# APM32F425 register map
File version: 1.0
CPU: CM4 r1p0, little endian, no MPU, no FPU, 4 interrupt priority bits
Registers are 32-bit, read-write, reset 0x0 unless marked. A register's access mark holds for its fields unless they carry their own. Offsets are from the block's base; [hi:lo] are bit positions.

## Ethernet_DMA — Ethernet: DMA controller operation
Base 0x40029000
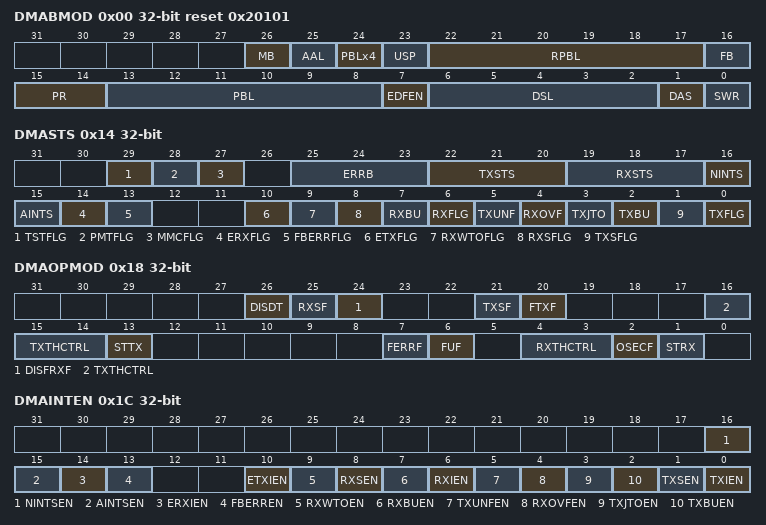
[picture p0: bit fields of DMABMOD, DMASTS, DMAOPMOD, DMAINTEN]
0x00 DMABMOD reset 0x20101 — Ethernet DMA bus mode register
  [26] MB — Mixed Burst
  [25] AAL — Address-Aligned Beats
  [24] PBLx4 — PBLx4 Mode
  [23] USP — Use Separate PBL
  [22:17] RPBL — Rx DMA PBL
  [16] FB — Fixed Burst
  [15:14] PR — Priority Ratio
  [13:8] PBL — Programmable Burst Length
  [7] EDFEN — Enhanced Descriptor Format Enable
  [6:2] DSL — Descriptor Skip Length
  [1] DAS — DMA Arbitration Scheme
  [0] SWR — Software Reset
0x04 DMATXPD — Ethernet DMA transmit poll demand register
  [31:0] TXPD — Transmit Poll Demand
0x08 DMARXPD — EHERNET DMA receive poll demand register
  [31:0] RXPD — Receive Poll Demand
0x0C DMARXDLADDR — Ethernet DMA receive descriptor list address register
  [31:0] RXSTA — Start of Receive List
0x10 DMATXDLADDR — Ethernet DMA transmit descriptor list address register
  [31:0] TXSTA — Start of Transmit List
0x14 DMASTS access per field — Ethernet DMA status register
  [29] TSTFLG ro — Timestamp Trigger Flag
  [28] PMTFLG ro — PMT Flag
  [27] MMCFLG ro — MMC Flag
  [25:23] ERRB ro — Error Bits
  [22:20] TXSTS ro — Transmit Process State
  [19:17] RXSTS ro — Receive Process State
  [16] NINTS rw — Normal Interrupt Summary
  [15] AINTS rw — Abnormal Interrupt Summary
  [14] ERXFLG rw — Early Receive Flag
  [13] FBERRFLG rw — Fatal Bus Error Flag
  [10] ETXFLG rw — Early Transmit Flag
  [9] RXWTOFLG rw — Receive Watchdog Timeout Flag
  [8] RXSFLG rw — Receive Stopped Flag
  [7] RXBU rw — Receive Buffer Unavailable
  [6] RXFLG rw — Receive Flag
  [5] TXUNF rw — Transmit Underflow
  [4] RXOVF rw — Receive Overflow
  [3] TXJTO rw — Transmit Jabber Timeout
  [2] TXBU rw — Transmit Buffer Unavailable
  [1] TXSFLG rw — Transmit Stopped Flag
  [0] TXFLG rw — Transmit Flag
0x18 DMAOPMOD — Ethernet DMA operation mode register
  [26] DISDT — Disable Dropping of TCP/IP Checksum Error Frames
  [25] RXSF — Receive Store and Forward
  [24] DISFRXF — Disable Flushing of Received Frames
  [21] TXSF — Transmit Store and Forward
  [20] FTXF — Flush Transmit FIFO
  [16:14] TXTHCTRL — Transmit Threshold Control
  [13] STTX — Start or Stop Transmission Command
  [7] FERRF — Forward Error Frames
  [6] FUF — Forward Undersized Good Frames
  [4:3] RXTHCTRL — Receive Threshold Control
  [2] OSECF — Operate on Second Frame
  [1] STRX — Start or Stop Receive
0x1C DMAINTEN — Ethernet DMA interrupt enable register
  [16] NINTSEN — Normal Interrupt Summary Enable
  [15] AINTSEN — Abnormal Interrupt Summary Enable
  [14] ERXIEN — Early Receive Interrupt Enable
  [13] FBERREN — Fatal Bus Error Enable
  [10] ETXIEN — Early Transmit Interrupt Enable
  [9] RXWTOEN — Receive Watchdog Timeout Enable
  [8] RXSEN — Receive Stopped Enable
  [7] RXBUEN — Receive Buffer Unavailable Enable
  [6] RXIEN — Receive Interrupt Enable
  [5] TXUNFEN — Transmit Underflow Interrupt Enable
  [4] RXOVFEN — Receive Overflow Interrupt Enable
  [3] TXJTOEN — Transmit Jabber Timeout Enable
  [2] TXBUEN — Transmit Buffer Unavailable Enable
  [1] TXSEN — Transmit Stopped Enable
  [0] TXIEN — Transmit Interrupt Enable
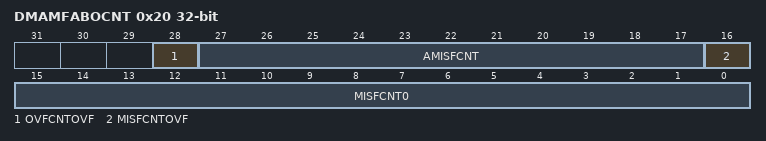
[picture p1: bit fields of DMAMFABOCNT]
0x20 DMAMFABOCNT — Ethernet DMA missed frame and buffer overflow counter register
  [28] OVFCNTOVF — Overflow Bit for FIFO Overflow Counter
  [27:17] AMISFCNT — Application Missed Frame Counter
  [16] MISFCNTOVF — Overflow Bit for Missed Frame Counter
  [15:0] MISFCNT0 — Missed Frame Counter
0x24 DMARXFLGWDT — Ethernet DMA receive status watchdog timer register
  [7:0] RXWDTCNT — RXFLG Watchdog Timer Count
0x48 DMAHTXD ro — Ethernet DMA current host transmit descriptor register
  [31:0] HTXDADDRP — Host Transmit Descriptor Address Pointer
0x4C DMAHRXD ro — Ethernet DMA current host receive descriptor register
  [31:0] HRXDADDRP — Host Receive Descriptor Address Pointer
0x50 DMAHTXBADDR ro — Ethernet DMA current host transmit buffer address register
  [31:0] HTXBADDRP — Host Transmit Buffer Address Pointer
0x54 DMAHRXBADDR ro — Ethernet DMA current host receive buffer address register
  [31:0] HRXBADDRP — Host Receive Buffer Address Pointer
